# M3HN_L register map
File version: 0.1
Registers are 32-bit, read-write, reset 0x0 unless marked. A register's access mark holds for its fields unless they carry their own. Offsets are from the block's base; [hi:lo] are bit positions; {n}, {i} and the like mark numbered series; 'fields as' and 'values as' point back to an identical list.

## RMC
Base 0x400E7000
0x00 EN — RMC Enable Register
  [0] RMCEN
0x04 REN — RMC Receive Enable Register
  [0] RMCREN
0x08 RBUF1 ro — RMC Receive Data Buffer Register 1
  [31:0] RMCRBUF
0x0C RBUF2 ro — RMC Receive Data Buffer Register 2
  [31:0] RMCRBUF
0x10 RBUF3 ro — RMC Receive Data Buffer Register 3
  [7:0] RMCRBUF
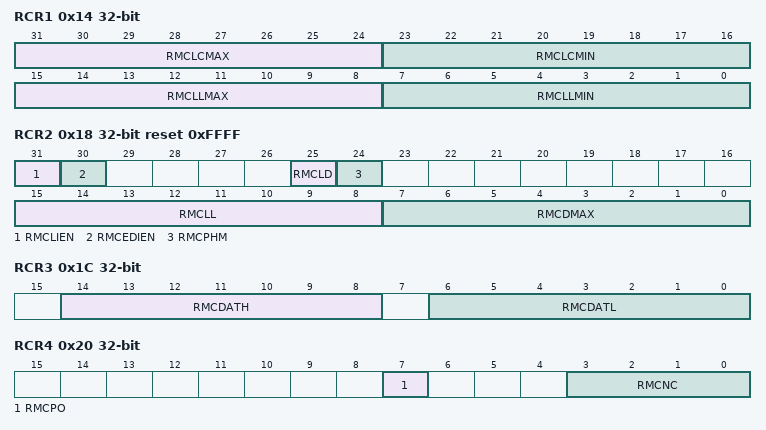
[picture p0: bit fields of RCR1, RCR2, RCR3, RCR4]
0x14 RCR1 — RMC Receive Control Register 1
  [31:24] RMCLCMAX, [23:16] RMCLCMIN, [15:8] RMCLLMAX, [7:0] RMCLLMIN
0x18 RCR2 reset 0xFFFF — RMC Receive Control Register 2
  [31] RMCLIEN, [30] RMCEDIEN, [25] RMCLD, [24] RMCPHM, [15:8] RMCLL, [7:0] RMCDMAX
0x1C RCR3 — RMC Receive Control Register 3
  [14:8] RMCDATH, [6:0] RMCDATL
0x20 RCR4 — RMC Receive Control Register 4
  [7] RMCPO, [3:0] RMCNC
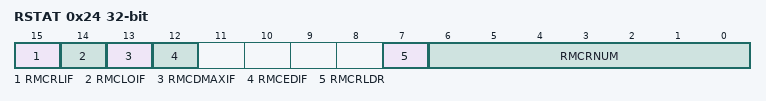
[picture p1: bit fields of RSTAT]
0x24 RSTAT ro — RMC Receive Status Register
  [15] RMCRLIF, [14] RMCLOIF, [13] RMCDMAXIF, [12] RMCEDIF, [7] RMCRLDR, [6:0] RMCRNUM
{0x24+4i} END{i} (i=1..3) — RMC Receive End Bit Number Register {i}
  [6:0] RMCEND{i}
0x34 FSSEL — RMC Frequency Selection Register
  [0] RMCCLK

## OFD
Base 0x400F1000
0x00 CR1 reset 0x6 — OFD Control Register 1
  [7:0] OFDWEN
0x04 CR2 — OFD Control Register 2
  [7:0] OFDEN
0x08 MN0 — OFD Lower Detection Frequency Setting Register0
  [11:0] OFDMN0
0x0C MN1 — OFD Lower Detection Frequency Setting Register1
  [11:0] OFDMN1
0x10 MX0 — OFD Higher Detection Frequency Setting Register0
  [11:0] OFDMX0
0x14 MX1 — OFD Higher Detection Frequency Setting Register1
  [11:0] OFDMX1
0x18 RST reset 0x1 — OFD Reset Enable Control Register
  [0] OFDRSTEN
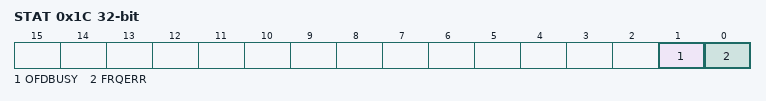
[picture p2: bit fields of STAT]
0x1C STAT ro — OFD Status Register
  [1] OFDBUSY, [0] FRQERR
0x20 MON reset 0x1 — OFD External high frequency oscillaion clock monitor register
  [0] OFDMON

## CG
Base 0x400F3000
0x00 PROTECT reset 0xC1 — CG Protect Register
  [7:0] PROTECT
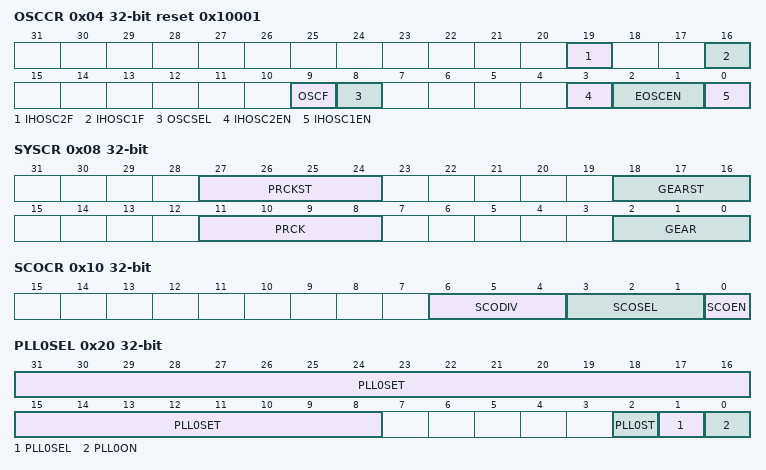
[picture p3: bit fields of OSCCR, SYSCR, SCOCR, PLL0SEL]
0x04 OSCCR reset 0x10001 — CG Oscillation Control Register
  [19] IHOSC2F ro, [16] IHOSC1F ro, [9] OSCF ro, [8] OSCSEL, [3] IHOSC2EN, [2:1] EOSCEN, [0] IHOSC1EN
0x08 SYSCR — CG System clock control register
  [27:24] PRCKST ro, [18:16] GEARST ro, [11:8] PRCK, [2:0] GEAR
0x0C STBYCR — CG Standby Control Register
  [1:0] STBY
0x10 SCOCR — CG SCOUT Control Register
  [6:4] SCODIV, [3:1] SCOSEL, [0] SCOEN
0x20 PLL0SEL — CG PLL select register for fsys
  [31:8] PLL0SET, [2] PLL0ST ro, [1] PLL0SEL, [0] PLL0ON
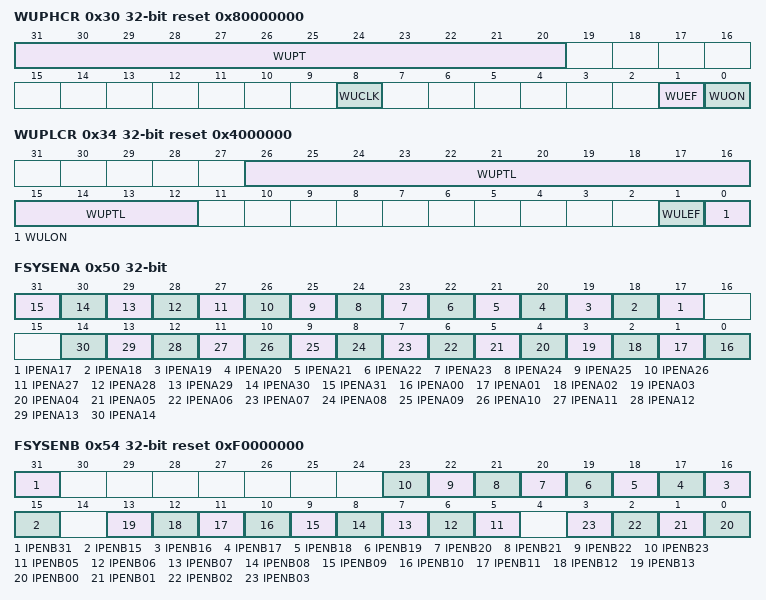
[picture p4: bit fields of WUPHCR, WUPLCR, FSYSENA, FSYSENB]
0x30 WUPHCR reset 0x80000000 — CG Warmup register for HOSC
  [31:20] WUPT, [8] WUCLK, [1] WUEF ro, [0] WUON wo
0x34 WUPLCR reset 0x4000000 — CG Low-speed oscillation warm-up register
  [26:12] WUPTL, [1] WULEF ro, [0] WULON wo
0x50 FSYSENA — CG output control register A for fsys clock
  [n] IPENA{n} (n=17..31), [n] IPENA{n:02} (n=0..14)
0x54 FSYSENB reset 0xF0000000 — CG output control register B for fsys clock
  [31] IPENB31, [n] IPENB{n} (n=15..23), [n] IPENB{n:02} (n=5..13), [n] IPENB{n:02} (n=0..3)
0x58 FCEN — CG output control register for fc clock
  [7] FCIPEN07
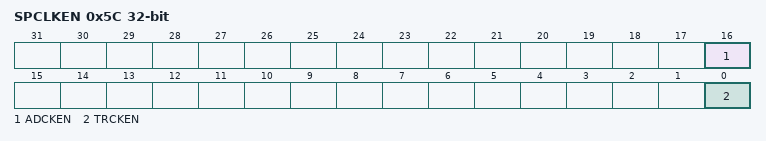
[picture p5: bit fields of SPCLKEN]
0x5C SPCLKEN — CG Output control register for ADC AND TRACE CLOCK
  [16] ADCKEN, [0] TRCKEN

## TRM
Base 0x400F3200
0x00 OSCPRO — TRM Protect register
  [7:0] PROTECT
0x04 OSCEN — TRM Enable register
  [0] TRIMEN
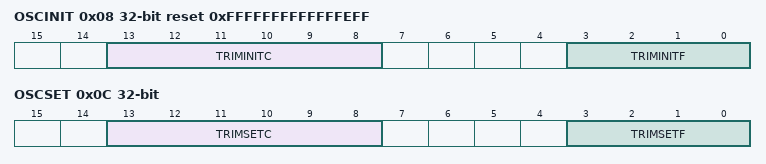
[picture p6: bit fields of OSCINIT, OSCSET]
0x08 OSCINIT ro reset 0xFFFFFFFFFFFFFEFF — TRM Initial trimming level monitor register
  [13:8] TRIMINITC, [3:0] TRIMINITF
0x0C OSCSET — TRM Trimming level setting register
  [13:8] TRIMSETC, [3:0] TRIMSETF

## IB — Interrupt control register B
Base 0x400F4E00
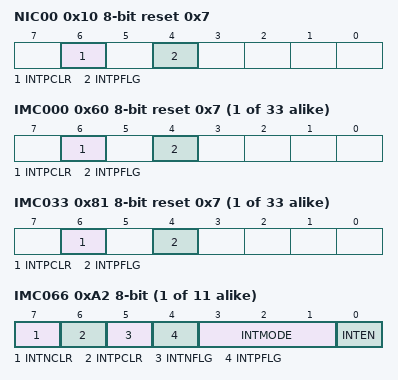
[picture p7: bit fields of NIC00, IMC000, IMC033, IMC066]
0x10 NIC00 8-bit reset 0x7 — Non makeable Interrupt Control(B) 00
  [6] INTPCLR wo, [4] INTPFLG ro
{0x60+i} IMC{i:03} 8-bit reset 0x7 (i=0..32) — Interrupu Mode Control Register(B) {i:03}
  [6] INTPCLR wo, [4] INTPFLG ro
{0x60+i} IMC{i:03} 8-bit reset 0x7 (i=33..65) — Interrupt Mode Control Register(B) {i:03}
  [6] INTPCLR wo, [4] INTPFLG ro
{0x60+i} IMC{i:03} 8-bit (i=66..76) — Interrupu Mode Control Register(B) {i:03}
  [7] INTNCLR wo, [6] INTPCLR wo, [5] INTNFLG ro, [4] INTPFLG ro, [3:1] INTMODE, [0] INTEN
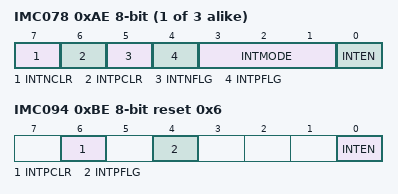
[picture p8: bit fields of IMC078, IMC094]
{0x60+i} IMC{i:03} 8-bit (i=78..80) — Interrupu Mode Control Register(B) {i:03}
  fields as IMC066
0xBE IMC094 8-bit reset 0x6 — Interrupu Mode Control Register(B) 094
  [6] INTPCLR wo, [4] INTPFLG ro, [0] INTEN
